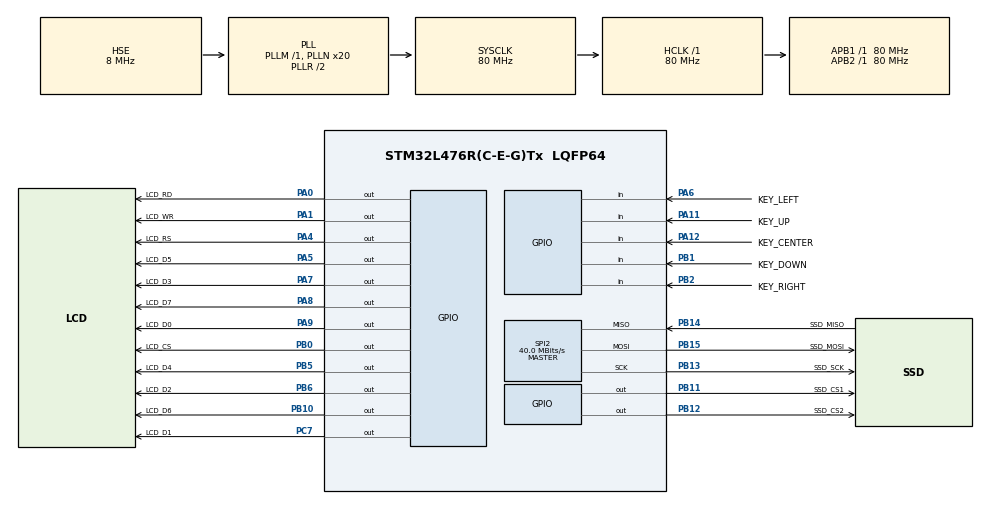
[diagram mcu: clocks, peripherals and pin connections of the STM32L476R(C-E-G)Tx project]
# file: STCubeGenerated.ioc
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Dma.Request0=SPI2_RX
Dma.Request1=SPI2_TX
Dma.SPI2_RX.0.Direction=DMA_PERIPH_TO_MEMORY
Dma.SPI2_RX.0.Instance=DMA1_Channel4
Dma.SPI2_RX.0.MemDataAlignment=DMA_MDATAALIGN_BYTE
Dma.SPI2_RX.0.MemInc=DMA_MINC_ENABLE
Dma.SPI2_RX.0.Mode=DMA_NORMAL
Dma.SPI2_RX.0.PeriphDataAlignment=DMA_PDATAALIGN_BYTE
Dma.SPI2_RX.0.PeriphInc=DMA_PINC_DISABLE
Dma.SPI2_RX.0.Priority=DMA_PRIORITY_LOW
Dma.SPI2_TX.1.Direction=DMA_MEMORY_TO_PERIPH
Dma.SPI2_TX.1.Instance=DMA1_Channel5
Dma.SPI2_TX.1.MemDataAlignment=DMA_MDATAALIGN_BYTE
Dma.SPI2_TX.1.MemInc=DMA_MINC_ENABLE
Dma.SPI2_TX.1.Mode=DMA_NORMAL
Dma.SPI2_TX.1.PeriphDataAlignment=DMA_PDATAALIGN_BYTE
Dma.SPI2_TX.1.PeriphInc=DMA_PINC_DISABLE
Dma.SPI2_TX.1.Priority=DMA_PRIORITY_LOW
Mcu.Family=STM32L4
Mcu.Name=STM32L476R(C-E-G)Tx
Mcu.Package=LQFP64
NVIC.DMA1_Channel4_IRQn=true\:0\:0\:false\:false\:true\:false\:true
NVIC.DMA1_Channel5_IRQn=true\:0\:0\:false\:false\:true\:false\:true
NVIC.PriorityGroup=NVIC_PRIORITYGROUP_4
PA0.GPIO_Label=LCD_RD
PA0.Signal=GPIO_Output
PA1.GPIO_Label=LCD_WR
PA1.Signal=GPIO_Output
PA11.GPIO_Label=KEY_UP
PA11.Signal=GPIO_Input
PA12.GPIO_Label=KEY_CENTER
PA12.Signal=GPIO_Input
PA13\ (JTMS-SWDIO).Mode=Trace_Asynchronous_SW
PA13\ (JTMS-SWDIO).Signal=SYS_JTMS-SWDIO
PA14\ (JTCK-SWCLK).Mode=Trace_Asynchronous_SW
PA14\ (JTCK-SWCLK).Signal=SYS_JTCK-SWCLK
PA4.GPIO_Label=LCD_RS
PA4.Signal=GPIO_Output
PA5.GPIO_Label=LCD_D5
PA5.Signal=GPIO_Output
PA6.GPIO_Label=KEY_LEFT
PA6.Signal=GPIO_Input
PA7.GPIO_Label=LCD_D3
PA7.Signal=GPIO_Output
PA8.GPIO_Label=LCD_D7
PA8.Signal=GPIO_Output
PA9.GPIO_Label=LCD_D0
PA9.Signal=GPIO_Output
PB0.GPIO_Label=LCD_CS
PB0.Signal=GPIO_Output
PB1.GPIO_Label=KEY_DOWN
PB1.Signal=GPIO_Input
PB10.GPIO_Label=LCD_D6
PB10.Signal=GPIO_Output
PB11.GPIO_Label=SSD_CS1
PB11.GPIO_Speed=GPIO_SPEED_FREQ_VERY_HIGH
PB11.PinState=GPIO_PIN_SET
PB11.Signal=GPIO_Output
PB12.GPIO_Label=SSD_CS2
PB12.GPIO_Speed=GPIO_SPEED_FREQ_VERY_HIGH
PB12.PinState=GPIO_PIN_SET
PB12.Signal=GPIO_Output
PB13.GPIO_Label=SSD_SCK
PB13.Mode=Full_Duplex_Master
PB13.Signal=SPI2_SCK
PB14.GPIO_Label=SSD_MISO
PB14.Mode=Full_Duplex_Master
PB14.Signal=SPI2_MISO
PB15.GPIO_Label=SSD_MOSI
PB15.Mode=Full_Duplex_Master
PB15.Signal=SPI2_MOSI
PB2.GPIO_Label=KEY_RIGHT
PB2.Signal=GPIO_Input
PB3\ (JTDO-TRACESWO).Mode=Trace_Asynchronous_SW
PB3\ (JTDO-TRACESWO).Signal=SYS_JTDO-SWO
PB5.GPIO_Label=LCD_D4
PB5.Signal=GPIO_Output
PB6.GPIO_Label=LCD_D2
PB6.Signal=GPIO_Output
PC7.GPIO_Label=LCD_D1
PC7.Signal=GPIO_Output
PH0-OSC_IN\ (PH0).Mode=HSE-External-Clock-Source
PH0-OSC_IN\ (PH0).Signal=RCC_OSC_IN
ProjectManager.HeapSize=0x200
ProjectManager.StackSize=0x400
ProjectManager.TargetToolchain=MDK-ARM V5
RCC.ADCFreq_Value=32000000
RCC.AHBFreq_Value=80000000
RCC.APB1Freq_Value=80000000
RCC.APB1TimFreq_Value=80000000
RCC.APB2Freq_Value=80000000
RCC.APB2TimFreq_Value=80000000
RCC.CortexFreq_Value=80000000
RCC.HCLKFreq_Value=80000000
RCC.HSE_VALUE=8000000
RCC.HSI_VALUE=16000000
RCC.LSE_VALUE=32768
RCC.MSI_VALUE=4000000
RCC.PLLN=20
RCC.PLLSourceVirtual=RCC_PLLSOURCE_HSE
RCC.SYSCLKFreq_VALUE=80000000
RCC.SYSCLKSource=RCC_SYSCLKSOURCE_PLLCLK
RCC.USBFreq_Value=32000000
RCC.VCOOutputFreq_Value=160000000
SPI2.BaudRatePrescaler=SPI_BAUDRATEPRESCALER_2
SPI2.CalculateBaudRate=40.0 MBits/s
SPI2.DataSize=SPI_DATASIZE_8BIT
SPI2.Direction=SPI_DIRECTION_2LINES
SPI2.Mode=SPI_MODE_MASTER
SPI2.VirtualType=VM_MASTER
board=custom

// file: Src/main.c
/* USER CODE BEGIN Header */
/**
  ******************************************************************************
  * @file           : main.c
  * @brief          : Main program body
  ******************************************************************************
  * @attention
  *
  * <h2><center>&copy; Copyright (c) 2019 STMicroelectronics.
  * All rights reserved.</center></h2>
  *
  * This software component is licensed by ST under BSD 3-Clause license,
  * the "License"; You may not use this file except in compliance with the
  * License. You may obtain a copy of the License at:
  *                        opensource.org/licenses/BSD-3-Clause
  *
  ******************************************************************************
  */
/* USER CODE END Header */

#include "main.h"

/* USER CODE BEGIN Includes */

#include "misc_macro.h"
// see https://www.keil.com/pack/doc/STM32Cube/General/html/cubemx__r_t_x.html
#include "cmsis_os2.h"                  // ARM::CMSIS:RTOS:Keil RTX

/* USER CODE END Includes */

SPI_HandleTypeDef hspi2;
DMA_HandleTypeDef hdma_spi2_rx;
DMA_HandleTypeDef hdma_spi2_tx;

void SystemClock_Config(void);
static void MX_GPIO_Init(void);
static void MX_DMA_Init(void);
static void MX_SPI2_Init(void);

/* USER CODE BEGIN 0 */

// see https://www.keil.com/pack/doc/STM32Cube/General/html/cubemx__r_t_x.html
// adapted for RTOS v2 API
uint32_t HAL_GetTick(void) {           // Add HAL_GetTick function for STM32Cube HAL
  return osKernelGetTickCount();
}

/* USER CODE END 0 */

int main(void)
{
  /* USER CODE BEGIN 1 */

  // see https://www.keil.com/pack/doc/STM32Cube/General/html/cubemx__r_t_x.html
  osKernelInitialize();               // Initialize RTOS Kernel for setup

  /* USER CODE END 1 */

  /* MCU Configuration--------------------------------------------------------*/

  /* Reset of all peripherals, Initializes the Flash interface and the Systick. */
  HAL_Init();

  /* Configure the system clock */
  SystemClock_Config();

  /* Initialize all configured peripherals */
  MX_GPIO_Init();
  MX_DMA_Init();
  MX_SPI2_Init();
  /* USER CODE BEGIN 2 */

  extern int cpp_main(void);
  cpp_main();

  /* USER CODE END 2 */

  /* Infinite loop */
  while (1)
  {

  }
}

void SystemClock_Config(void)
{
  RCC_OscInitTypeDef RCC_OscInitStruct = {0};
  RCC_ClkInitTypeDef RCC_ClkInitStruct = {0};

  /** Initializes the CPU, AHB and APB busses clocks
  */
  RCC_OscInitStruct.OscillatorType = RCC_OSCILLATORTYPE_HSE;
  RCC_OscInitStruct.HSEState = RCC_HSE_BYPASS;
  RCC_OscInitStruct.PLL.PLLState = RCC_PLL_ON;
  RCC_OscInitStruct.PLL.PLLSource = RCC_PLLSOURCE_HSE;
  RCC_OscInitStruct.PLL.PLLM = 1;
  RCC_OscInitStruct.PLL.PLLN = 20;
  RCC_OscInitStruct.PLL.PLLP = RCC_PLLP_DIV7;
  RCC_OscInitStruct.PLL.PLLQ = RCC_PLLQ_DIV2;
  RCC_OscInitStruct.PLL.PLLR = RCC_PLLR_DIV2;
  if (HAL_RCC_OscConfig(&RCC_OscInitStruct) != HAL_OK)
  {
    Error_Handler();
  }
  /** Initializes the CPU, AHB and APB busses clocks
  */
  RCC_ClkInitStruct.ClockType = RCC_CLOCKTYPE_HCLK|RCC_CLOCKTYPE_SYSCLK
                              |RCC_CLOCKTYPE_PCLK1|RCC_CLOCKTYPE_PCLK2;
  RCC_ClkInitStruct.SYSCLKSource = RCC_SYSCLKSOURCE_PLLCLK;
  RCC_ClkInitStruct.AHBCLKDivider = RCC_SYSCLK_DIV1;
  RCC_ClkInitStruct.APB1CLKDivider = RCC_HCLK_DIV1;
  RCC_ClkInitStruct.APB2CLKDivider = RCC_HCLK_DIV1;

  if (HAL_RCC_ClockConfig(&RCC_ClkInitStruct, FLASH_LATENCY_4) != HAL_OK)
  {
    Error_Handler();
  }
  /** Configure the main internal regulator output voltage
  */
  if (HAL_PWREx_ControlVoltageScaling(PWR_REGULATOR_VOLTAGE_SCALE1) != HAL_OK)
  {
    Error_Handler();
  }
}

static void MX_SPI2_Init(void)
{

  /* SPI2 parameter configuration*/
  hspi2.Instance = SPI2;
  hspi2.Init.Mode = SPI_MODE_MASTER;
  hspi2.Init.Direction = SPI_DIRECTION_2LINES;
  hspi2.Init.DataSize = SPI_DATASIZE_8BIT;
  hspi2.Init.CLKPolarity = SPI_POLARITY_LOW;
  hspi2.Init.CLKPhase = SPI_PHASE_1EDGE;
  hspi2.Init.NSS = SPI_NSS_SOFT;
  hspi2.Init.BaudRatePrescaler = SPI_BAUDRATEPRESCALER_2;
  hspi2.Init.FirstBit = SPI_FIRSTBIT_MSB;
  hspi2.Init.TIMode = SPI_TIMODE_DISABLE;
  hspi2.Init.CRCCalculation = SPI_CRCCALCULATION_DISABLE;
  hspi2.Init.CRCPolynomial = 7;
  hspi2.Init.CRCLength = SPI_CRC_LENGTH_DATASIZE;
  hspi2.Init.NSSPMode = SPI_NSS_PULSE_ENABLE;
  if (HAL_SPI_Init(&hspi2) != HAL_OK)
  {
    Error_Handler();
  }

}

static void MX_DMA_Init(void)
{
  /* DMA controller clock enable */
  __HAL_RCC_DMA1_CLK_ENABLE();

  /* DMA interrupt init */
  /* DMA1_Channel4_IRQn interrupt configuration */
  HAL_NVIC_SetPriority(DMA1_Channel4_IRQn, 0, 0);
  HAL_NVIC_EnableIRQ(DMA1_Channel4_IRQn);
  /* DMA1_Channel5_IRQn interrupt configuration */
  HAL_NVIC_SetPriority(DMA1_Channel5_IRQn, 0, 0);
  HAL_NVIC_EnableIRQ(DMA1_Channel5_IRQn);

}

static void MX_GPIO_Init(void)
{
  GPIO_InitTypeDef GPIO_InitStruct = {0};

  /* GPIO Ports Clock Enable */
  __HAL_RCC_GPIOH_CLK_ENABLE();
  __HAL_RCC_GPIOA_CLK_ENABLE();
  __HAL_RCC_GPIOB_CLK_ENABLE();
  __HAL_RCC_GPIOC_CLK_ENABLE();

  /*Configure GPIO pin Output Level */
  HAL_GPIO_WritePin(GPIOA, LCD_RD_Pin|LCD_WR_Pin|LCD_RS_Pin|LCD_D5_Pin
                          |LCD_D3_Pin|LCD_D7_Pin|LCD_D0_Pin, GPIO_PIN_RESET);

  /*Configure GPIO pin Output Level */
  HAL_GPIO_WritePin(GPIOB, LCD_CS_Pin|LCD_D6_Pin|LCD_D4_Pin|LCD_D2_Pin, GPIO_PIN_RESET);

  /*Configure GPIO pin Output Level */
  HAL_GPIO_WritePin(GPIOB, SSD_CS1_Pin|SSD_CS2_Pin, GPIO_PIN_SET);

  /*Configure GPIO pin Output Level */
  HAL_GPIO_WritePin(LCD_D1_GPIO_Port, LCD_D1_Pin, GPIO_PIN_RESET);

  /*Configure GPIO pins : LCD_RD_Pin LCD_WR_Pin LCD_RS_Pin LCD_D5_Pin
                           LCD_D3_Pin LCD_D7_Pin LCD_D0_Pin */
  GPIO_InitStruct.Pin = LCD_RD_Pin|LCD_WR_Pin|LCD_RS_Pin|LCD_D5_Pin
                          |LCD_D3_Pin|LCD_D7_Pin|LCD_D0_Pin;
  GPIO_InitStruct.Mode = GPIO_MODE_OUTPUT_PP;
  GPIO_InitStruct.Pull = GPIO_NOPULL;
  GPIO_InitStruct.Speed = GPIO_SPEED_FREQ_LOW;
  HAL_GPIO_Init(GPIOA, &GPIO_InitStruct);

  /*Configure GPIO pins : KEY_LEFT_Pin KEY_UP_Pin KEY_CENTER_Pin */
  GPIO_InitStruct.Pin = KEY_LEFT_Pin|KEY_UP_Pin|KEY_CENTER_Pin;
  GPIO_InitStruct.Mode = GPIO_MODE_INPUT;
  GPIO_InitStruct.Pull = GPIO_NOPULL;
  HAL_GPIO_Init(GPIOA, &GPIO_InitStruct);

  /*Configure GPIO pins : LCD_CS_Pin LCD_D6_Pin LCD_D4_Pin LCD_D2_Pin */
  GPIO_InitStruct.Pin = LCD_CS_Pin|LCD_D6_Pin|LCD_D4_Pin|LCD_D2_Pin;
  GPIO_InitStruct.Mode = GPIO_MODE_OUTPUT_PP;
  GPIO_InitStruct.Pull = GPIO_NOPULL;
  GPIO_InitStruct.Speed = GPIO_SPEED_FREQ_LOW;
  HAL_GPIO_Init(GPIOB, &GPIO_InitStruct);

  /*Configure GPIO pins : KEY_DOWN_Pin KEY_RIGHT_Pin */
  GPIO_InitStruct.Pin = KEY_DOWN_Pin|KEY_RIGHT_Pin;
  GPIO_InitStruct.Mode = GPIO_MODE_INPUT;
  GPIO_InitStruct.Pull = GPIO_NOPULL;
  HAL_GPIO_Init(GPIOB, &GPIO_InitStruct);

  /*Configure GPIO pins : SSD_CS1_Pin SSD_CS2_Pin */
  GPIO_InitStruct.Pin = SSD_CS1_Pin|SSD_CS2_Pin;
  GPIO_InitStruct.Mode = GPIO_MODE_OUTPUT_PP;
  GPIO_InitStruct.Pull = GPIO_NOPULL;
  GPIO_InitStruct.Speed = GPIO_SPEED_FREQ_VERY_HIGH;
  HAL_GPIO_Init(GPIOB, &GPIO_InitStruct);

  /*Configure GPIO pin : LCD_D1_Pin */
  GPIO_InitStruct.Pin = LCD_D1_Pin;
  GPIO_InitStruct.Mode = GPIO_MODE_OUTPUT_PP;
  GPIO_InitStruct.Pull = GPIO_NOPULL;
  GPIO_InitStruct.Speed = GPIO_SPEED_FREQ_LOW;
  HAL_GPIO_Init(LCD_D1_GPIO_Port, &GPIO_InitStruct);

}

void Error_Handler(void)
{
  /* USER CODE BEGIN Error_Handler_Debug */
  BRK_PTR();
  /* User can add his own implementation to report the HAL error return state */
  /* USER CODE END Error_Handler_Debug */
}

/************************ (C) COPYRIGHT STMicroelectronics *****END OF FILE****/
